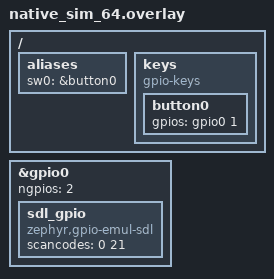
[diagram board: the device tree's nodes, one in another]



/ {
	aliases {
		sw0 = &button0;
	};

	keys: keys {
		compatible = "gpio-keys";
		button0: button0 {
			gpios = <&gpio0 1 GPIO_ACTIVE_HIGH>;
		};
	};

};

&gpio0 {
	ngpios = <2>;

	sdl_gpio {
		status = "okay";
		compatible = "zephyr,gpio-emul-sdl";
		/* Skip pin 0 with the unknown code 0 */
		scancodes = <0 21>;
	};
};
